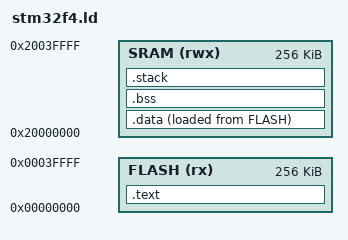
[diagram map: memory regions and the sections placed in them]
MEMORY
{
    FLASH (rx)  : ORIGIN = 0x00000000, LENGTH = 256K
    SRAM  (rwx) : ORIGIN = 0x20000000, LENGTH = 256K
}

SECTIONS
{
    .text :
    {
        KEEP(*(.isr_vector))
        *(.text*)
        *(.rodata*)
    } > FLASH

    .data :
    {
        *(.data*)
    } > SRAM AT > FLASH

    .bss :
    {
        *(.bss*)
        *(COMMON)
    } > SRAM

    .stack (NOLOAD) :
    {
        . = ALIGN(8);
        . = . + 0x1000;
        . = ALIGN(8);
    } > SRAM
}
